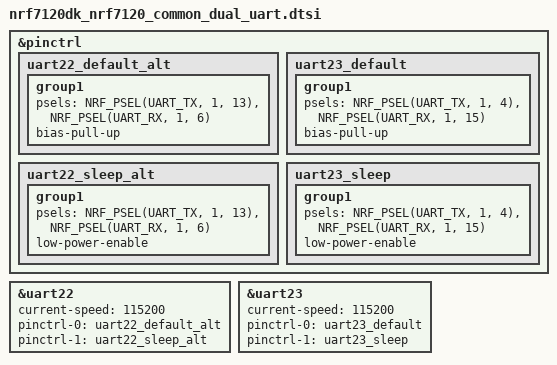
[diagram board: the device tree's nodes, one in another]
/*
 * Copyright (c) 2026 Nordic Semiconductor ASA
 *
 * SPDX-License-Identifier: Apache-2.0
 */

&pinctrl {
	uart22_default_alt: uart22_default_alt {
		group1 {
			psels = <NRF_PSEL(UART_TX, 1, 13)>,
				<NRF_PSEL(UART_RX, 1, 6)>;
			bias-pull-up;
		};
	};

	uart22_sleep_alt: uart22_sleep_alt {
		group1 {
			psels = <NRF_PSEL(UART_TX, 1, 13)>,
				<NRF_PSEL(UART_RX, 1, 6)>;
			low-power-enable;
		};
	};

	uart23_default: uart23_default {
		group1 {
			psels = <NRF_PSEL(UART_TX, 1, 4)>,
				<NRF_PSEL(UART_RX, 1, 15)>;
			bias-pull-up;
		};
	};

	uart23_sleep: uart23_sleep {
		group1 {
			psels = <NRF_PSEL(UART_TX, 1, 4)>,
				<NRF_PSEL(UART_RX, 1, 15)>;
			low-power-enable;
		};
	};
};

dut: &uart22 {
	status = "okay";
	current-speed = <115200>;
	pinctrl-0 = <&uart22_default_alt>;
	pinctrl-1 = <&uart22_sleep_alt>;
	pinctrl-names = "default", "sleep";
};

dut_aux: &uart23 {
	status = "okay";
	current-speed = <115200>;
	pinctrl-0 = <&uart23_default>;
	pinctrl-1 = <&uart23_sleep>;
	pinctrl-names = "default", "sleep";
};
